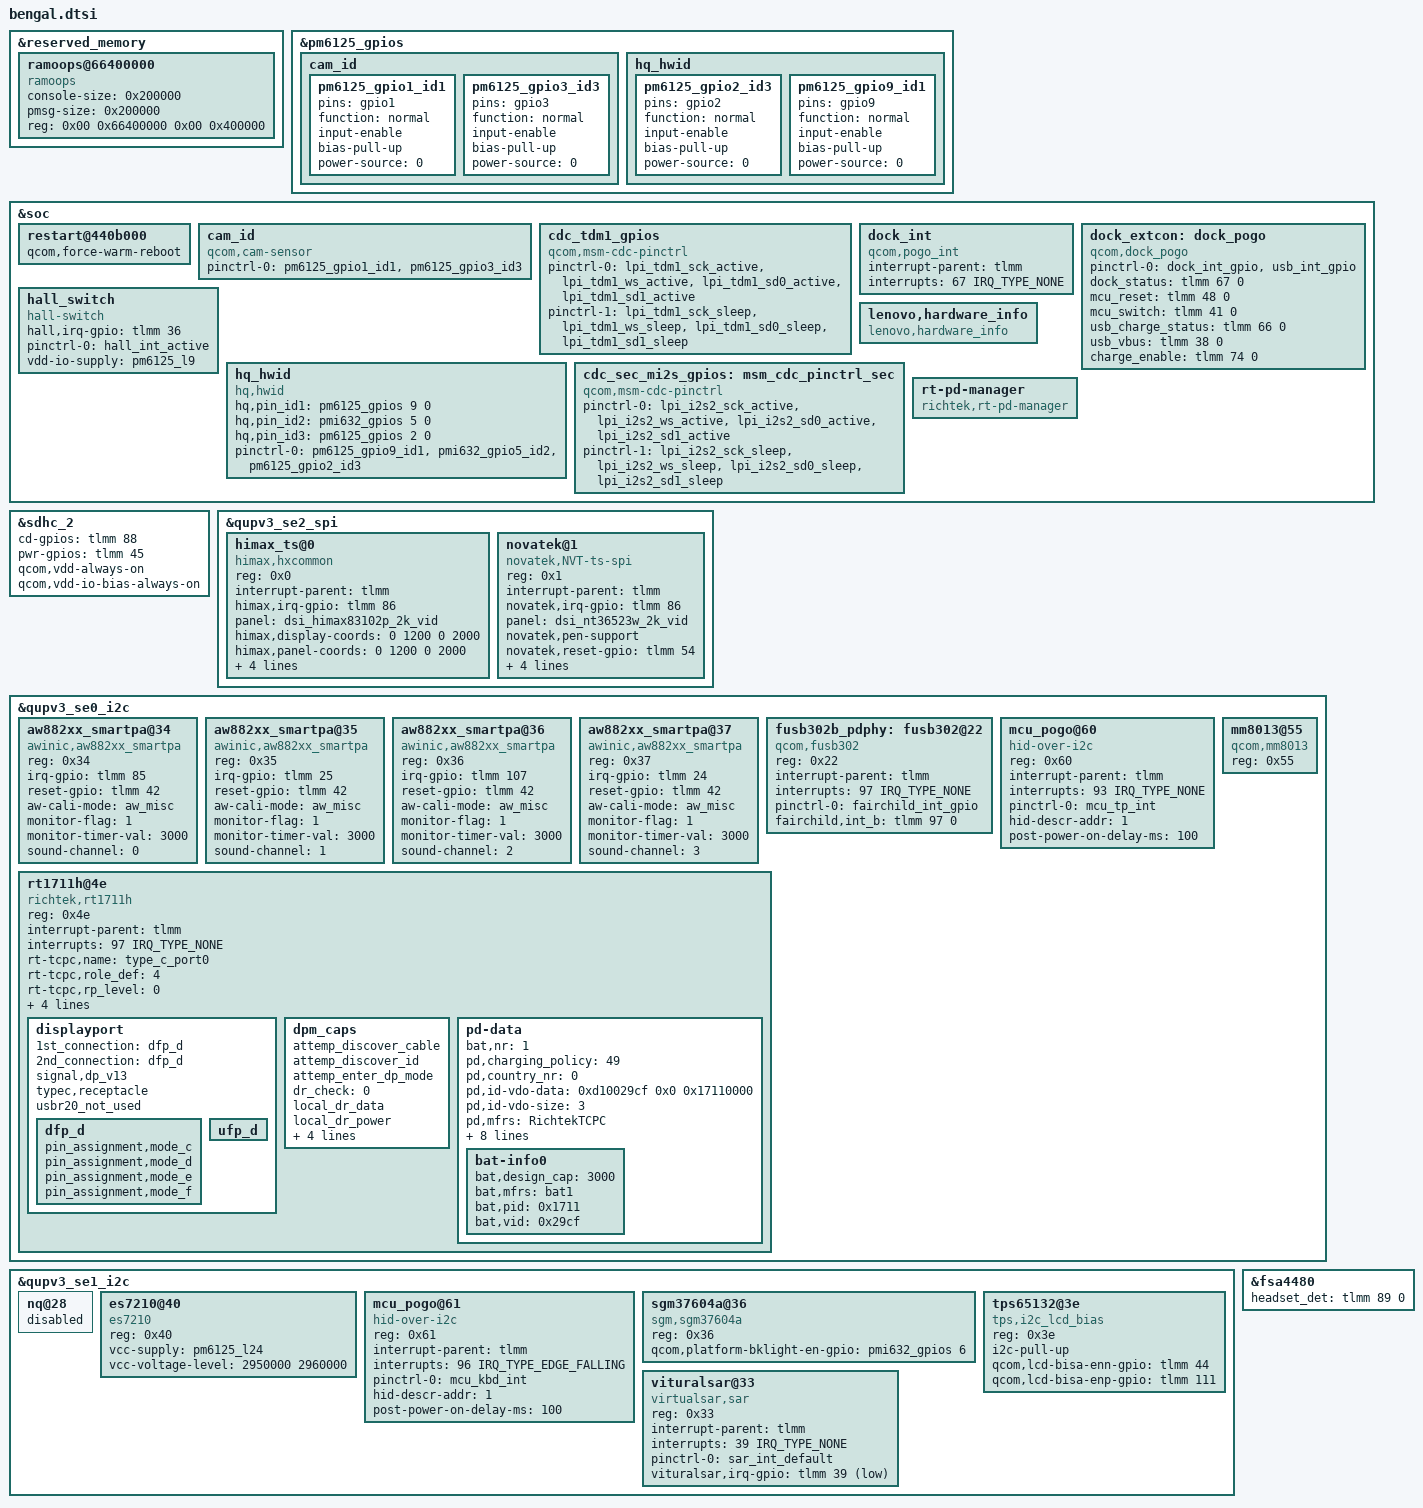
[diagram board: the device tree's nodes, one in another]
#include "bengal-usb.dtsi"
#include "bengal-pmi632.dtsi"

#include "bengal-pinctrl.dtsi"
#include "bengal-qupv3.dtsi"
#include "bengal-audio.dtsi"

#include "pm8008.dtsi"

// #include "bengal-thermal.dtsi"
#include "camera/bengal-camera.dtsi"

#include "bengal-sde-display.dtsi"

&reserved_memory {
	ramoops@66400000 {
		compatible = "ramoops";
		console-size = <0x200000>;
		pmsg-size = <0x200000>;
		reg = <0x00 0x66400000 0x00 0x400000>;
	};
};

&pm6125_gpios {
	cam_id {
		pm6125_gpio1_id1: pm6125_gpio1_id1 {
			pins = "gpio1";
			function = "normal";
			input-enable;
			bias-pull-up;
			power-source = <0>;
		};

		pm6125_gpio3_id3: pm6125_gpio3_id3 {
			pins = "gpio3";
			function = "normal";
			input-enable;
			bias-pull-up;
			power-source = <0>;
		};
	};

	hq_hwid {
		pm6125_gpio2_id3: pm6125_gpio2_id3 {
			pins = "gpio2";
			function = "normal";
			input-enable;
			bias-pull-up;
			power-source = <0>;
		};

		pm6125_gpio9_id1: pm6125_gpio9_id1 {
			pins = "gpio9";
			function = "normal";
			input-enable;
			bias-pull-up;
			power-source = <0>;
		};
	};
};

&soc {
	restart@440b000 {
		qcom,force-warm-reboot;
	};

	cam_id {
		compatible = "qcom,cam-sensor";
		pinctrl-names = "default";
		pinctrl-0 = <&pm6125_gpio1_id1 &pm6125_gpio3_id3>;
		status = "ok";
	};

	cdc_tdm1_gpios: cdc_tdm1_gpios {
		compatible = "qcom,msm-cdc-pinctrl";
		pinctrl-names = "aud_active", "aud_sleep";
		pinctrl-0 = <&lpi_tdm1_sck_active &lpi_tdm1_ws_active &lpi_tdm1_sd0_active &lpi_tdm1_sd1_active>;
		pinctrl-1 = <&lpi_tdm1_sck_sleep &lpi_tdm1_ws_sleep &lpi_tdm1_sd0_sleep &lpi_tdm1_sd1_sleep>;
	};

	dock_int {
		compatible = "qcom,pogo_int";
		interrupt-parent = <&tlmm>;
		interrupts = <67 IRQ_TYPE_NONE>;
	};

	dock_extcon: dock_pogo {
		compatible = "qcom,dock_pogo";
		pinctrl-names = "default";
		pinctrl-0 = <&dock_int_gpio>, <&usb_int_gpio>;
		dock_status = <&tlmm 67 0>;
		mcu_reset = <&tlmm 48 0>;
		mcu_switch = <&tlmm 41 0>;
		usb_charge_status = <&tlmm 66 0>;
		usb_vbus = <&tlmm 38 0>;
		charge_enable = <&tlmm 74 0>;
	};

	hall_switch {
		compatible = "hall-switch";
		hall,irq-gpio = <&tlmm 36 0>;
		pinctrl-names = "default";
		pinctrl-0 = <&hall_int_active>;
		vdd-io-supply = <&pm6125_l9>;
		status = "ok";
	};

	hq_hwid {
		compatible = "hq,hwid";
		hq,pin_id1 = <&pm6125_gpios 9 0>;
		hq,pin_id2 = <&pmi632_gpios 5 0>;
		hq,pin_id3 = <&pm6125_gpios 2 0>;
		pinctrl-names = "default";
		pinctrl-0 = <&pm6125_gpio9_id1 &pmi632_gpio5_id2 &pm6125_gpio2_id3>;
		status = "ok";
	};

	lenovo,hardware_info {
		compatible = "lenovo,hardware_info";
		status = "ok";
	};

	cdc_sec_mi2s_gpios: msm_cdc_pinctrl_sec {
		compatible = "qcom,msm-cdc-pinctrl";
		pinctrl-names = "aud_active", "aud_sleep";
		pinctrl-0 = <&lpi_i2s2_sck_active &lpi_i2s2_ws_active &lpi_i2s2_sd0_active &lpi_i2s2_sd1_active>;
		pinctrl-1 = <&lpi_i2s2_sck_sleep &lpi_i2s2_ws_sleep &lpi_i2s2_sd0_sleep &lpi_i2s2_sd1_sleep>;
	};

	rt-pd-manager {
		compatible = "richtek,rt-pd-manager";
	};
};

&sdhc_2 {
	cd-gpios = <&tlmm 88 0>;
	pwr-gpios = <&tlmm 45 0>;
	qcom,vdd-always-on;
	qcom,vdd-io-bias-always-on;
};

&qupv3_se2_spi {
	himax_ts@0 {
		compatible = "himax,hxcommon";
		reg = <0x0>;
		interrupt-parent = <&tlmm>;
		himax,irq-gpio = <&tlmm 86 8200>;
		panel = <&dsi_himax83102p_2k_vid>;
		himax,display-coords = <0 1200 0 2000>;
		himax,panel-coords = <0 1200 0 2000>;
		himax,rst-gpio = <&tlmm 54 0>;
		report_type = <1>;
		spi-cpha;
		spi-max-frequency = <10000000>;
	};

	novatek@1 {
		compatible = "novatek,NVT-ts-spi";
		reg = <0x1>;
		interrupt-parent = <&tlmm>;
		novatek,irq-gpio = <&tlmm 86 8200>;
		panel = <&dsi_nt36523w_2k_vid>;
		novatek,pen-support;
		novatek,reset-gpio = <&tlmm 54 0>;
		novatek,spi-rd-fast-addr = <258832>;
		novatek,swrst-n8-addr = <258302>;
		novatek,wgp-stylus;
		spi-max-frequency = <9600000>;
	};
};

&qupv3_se0_i2c {
	aw882xx_smartpa@34 {
		compatible = "awinic,aw882xx_smartpa";
		reg = <0x34>;
		irq-gpio = <&tlmm 85 0>;
		reset-gpio = <&tlmm 42 0>;
		aw-cali-mode = "aw_misc";
		monitor-flag = <1>;
		monitor-timer-val = <3000>;
		sound-channel = <0>;
	};

	aw882xx_smartpa@35 {
		compatible = "awinic,aw882xx_smartpa";
		reg = <0x35>;
		irq-gpio = <&tlmm 25 0>;
		reset-gpio = <&tlmm 42 0>;
		aw-cali-mode = "aw_misc";
		monitor-flag = <1>;
		monitor-timer-val = <3000>;
		sound-channel = <1>;
	};

	aw882xx_smartpa@36 {
		compatible = "awinic,aw882xx_smartpa";
		reg = <0x36>;
		irq-gpio = <&tlmm 107 0>;
		reset-gpio = <&tlmm 42 0>;
		aw-cali-mode = "aw_misc";
		monitor-flag = <1>;
		monitor-timer-val = <3000>;
		sound-channel = <2>;
	};

	aw882xx_smartpa@37 {
		compatible = "awinic,aw882xx_smartpa";
		reg = <0x37>;
		irq-gpio = <&tlmm 24 0>;
		reset-gpio = <&tlmm 42 0>;
		aw-cali-mode = "aw_misc";
		monitor-flag = <1>;
		monitor-timer-val = <3000>;
		sound-channel = <3>;
	};

	fusb302b_pdphy: fusb302@22 {
		compatible = "qcom,fusb302";
		reg = <0x22>;
		interrupt-parent = <&tlmm>;
		interrupts = <97 IRQ_TYPE_NONE>;
		pinctrl-names = "fairchild_enable_int";
		pinctrl-0 = <&fairchild_int_gpio>;
		fairchild,int_b = <&tlmm 97 0>;
	};

	mcu_pogo@60 {
		compatible = "hid-over-i2c";
		reg = <0x60>;
		interrupt-parent = <&tlmm>;
		interrupts = <93 IRQ_TYPE_NONE>;
		pinctrl-names = "default";
		pinctrl-0 = <&mcu_tp_int>;
		hid-descr-addr = <1>;
		post-power-on-delay-ms = <100>;
	};

	mm8013@55 {
		compatible = "qcom,mm8013";
		reg = <0x55>;
		status = "ok";
	};

	rt1711h@4e {
		compatible = "richtek,rt1711h";
		reg = <0x4e>;
		interrupt-parent = <&tlmm>;
		interrupts = <97 IRQ_TYPE_NONE>;
		rt-tcpc,name = "type_c_port0";
		rt-tcpc,role_def = <4>;
		rt-tcpc,rp_level = <0>;
		rt-tcpc,vconn_supply = <1>;
		rt1711pd,intr_gpio = <&tlmm 97 0>;
		rt1711pd,intr_gpio_num = <97>;
		tcpc-dual,supported_modes = <0>;

		displayport {
			1st_connection = "dfp_d";
			2nd_connection = "dfp_d";
			signal,dp_v13;
			typec,receptacle;
			usbr20_not_used;

			dfp_d {
				pin_assignment,mode_c;
				pin_assignment,mode_d;
				pin_assignment,mode_e;
				pin_assignment,mode_f;
			};

			ufp_d {
			};
		};

		dpm_caps {
			attemp_discover_cable;
			attemp_discover_id;
			attemp_enter_dp_mode;
			dr_check = <0>;
			local_dr_data;
			local_dr_power;
			local_no_suspend;
			local_usb_comm;
			local_vconn_supply;
			pr_check = <0>;
		};

		pd-data {
			bat,nr = <1>;
			pd,charging_policy = <49>;
			pd,country_nr = <0>;
			pd,id-vdo-data = <0xd10029cf 0x0 0x17110000>;
			pd,id-vdo-size = <3>;
			pd,mfrs = "RichtekTCPC";
			pd,pid = <0x1711>;
			pd,sink-pdo-data = <102600>;
			pd,sink-pdo-size = <1>;
			pd,source-cap-ext = <0x171129cf 0 0 0 0 0x2000000>;
			pd,source-pdo-data = <102450>;
			pd,source-pdo-size = <1>;
			pd,vid = <0x29cf>;

			bat-info0 {
				bat,design_cap = <3000>;
				bat,mfrs = "bat1";
				bat,pid = <0x1711>;
				bat,vid = <0x29cf>;
			};
		};
	};
};

&qupv3_se1_i2c {
	nq@28 {
		status = "disabled";
	};

	es7210@40 {
		compatible = "es7210";
		reg = <0x40>;
		vcc-supply = <&pm6125_l24>;
		vcc-voltage-level = <2950000 2960000>;
	};

	mcu_pogo@61 {
		compatible = "hid-over-i2c";
		reg = <0x61>;
		interrupt-parent = <&tlmm>;
		interrupts = <96 IRQ_TYPE_EDGE_FALLING>;
		pinctrl-names = "default";
		pinctrl-0 = <&mcu_kbd_int>;
		hid-descr-addr = <1>;
		post-power-on-delay-ms = <100>;
	};

	sgm37604a@36 {
		compatible = "sgm,sgm37604a";
		reg = <0x36>;
		qcom,platform-bklight-en-gpio = <&pmi632_gpios 6 0>;
	};

	tps65132@3e {
		compatible = "tps,i2c_lcd_bias";
		reg = <0x3e>;
		i2c-pull-up;
		qcom,lcd-bisa-enn-gpio = <&tlmm 44 0>;
		qcom,lcd-bisa-enp-gpio = <&tlmm 111 0>;
	};

	vituralsar@33 {
		compatible = "virtualsar,sar";
		reg = <0x33>;
		interrupt-parent = <&tlmm>;
		interrupts = <39 IRQ_TYPE_NONE>;
		pinctrl-names = "default";
		pinctrl-0 = <&sar_int_default>;
		vituralsar,irq-gpio = <&tlmm 39 3>;
	};
};

&fsa4480 {
	headset_det = <&tlmm 89 0>;
};
